# SWM341 register map
File version: 1.0
SWM341 Microcontroller registers
CPU: CM0 r1p0, little endian, MPU, FPU, 2 interrupt priority bits
Registers are 32-bit, read-write, no defined reset value unless marked. A register's access mark holds for its fields unless they carry their own. Offsets are from the block's base; lines under a group give offsets from that group; [hi:lo] are bit positions; {n}, {i} and the like mark numbered series; 'fields as' and 'values as' point back to an identical list; <NAME> marks a mode.

## Memory map
0x40000000 SYS size 0xAA09C — Registers group
0x40000800 DMA size 0x140 — Registers group
0x40001800 SDIO size 0x40 — Registers group
0x40002000 LCD size 0x114 — Registers group
0x40002800 CRC size 0x10 — Registers group
0x40003000 CORDIC size 0x20 — Registers group
0x40003800 DIV size 0x28 — Registers group
0x40004000 GPIOM size 0x80
0x40004800 GPION size 0x80
0x40005000 USBD size 0x4844 — Registers group
0x40005000 USBH size 0x5098 — Registers group
0x4000B000 JPEG size 0x400 — Registers group
0x4000C000 DMA2D size 0x44 — Registers group
0x40040000 GPIOA size 0x80 — Registers group
0x40040800 GPIOB size 0x80
0x40041000 GPIOC size 0x80
0x40041800 GPIOD size 0x80
0x40042000 UART0 size 0x20 — Registers group
0x40042800 UART1 size 0x20
0x40043000 UART2 size 0x20
0x40043800 UART3 size 0x20
0x40044000 SPI0 size 0x1C — Registers group
0x40044800 SPI1 size 0x1C
0x40046000 PWM0 size 0x80 — Registers group
0x40046080 PWM1 size 0x80
0x40046100 PWM2 size 0x80
0x40046180 PWM3 size 0x80
0x40046200 PWM4 size 0x80
0x40046400 PWMG size 0x28 — Registers group
0x40046800 TIMR0 size 0x34 — Registers group
0x40046840 TIMR1 size 0x34
0x40046880 TIMR2 size 0x34
0x400468C0 TIMR3 size 0x34
0x40046900 TIMR4 size 0x34
0x40046C00 TIMRG size 0x44 — Registers group
{0x40048800+0x40*n} BTIMR{n} size 0x34 (n=0..11)
0x40048C00 BTIMRG size 0x44
0x40049000 ADC0 size 0xF4 — Registers group
0x40049800 ADC1 size 0xF4
0x4004A000 FMC size 0x28 — Registers group
0x4004A800 SFC size 0x28 — Registers group
0x4004B800 RTC size 0x34 — Registers group
0x4004C000 DAC size 0x10 — Registers group
0x4004C800 QEI size 0x34 — Registers group
0x400A0000 PORTA size 0x504 — Registers group
0x400A0010 PORTB size 0x504
0x400A0020 PORTC size 0x504
0x400A0030 PORTD size 0x504
0x400A0040 PORTE size 0x504
0x400A0080 PORTM size 0x504
0x400A0090 PORTN size 0x504
0x400A0800 WDT size 0x14 — Registers group
0x400A1000 GPIOE size 0x80
0x400A6000 I2C0 size 0x38 — Registers group
0x400A6800 I2C1 size 0x38
0x400A8000 CAN0 size 0x3C0 — Registers group
0x400A8800 CAN1 size 0x3C0
0x88000000 SDRAMC size 0x14 — Registers group

## Interrupts
0 UART0 — UART0 global interrupt
1 UART1 — UART1 global interrupt
2 TIMR0 — TIMR0 global interrupt
3 TIMR1 — TIMR1 global interrupt
4 DMA — DMA global interrupt
5 SPI0 — SPI0 global interrupt
6 PWM_CH0 (PWM0) — PWM_CH0 global interrupt
7 WDT — WDT global interrupt
8 UART2 — UART2 global interrupt
9 PWM_CH1 (PWM1) — PWM_CH1 global interrupt
10 SARADC0 (ADC0) — SARADC0 global interrupt
11 BTIMER0 (BTIMR0) — BTIMER0 global interrupt
12 HALL0 (TIMRG) — HALL0 global interrupt
13 PWM_CH2 (PWM2) — PWM_CH2 global interrupt
14 PWM_HALT (PWMG) — PWM_HALT global interrupt
15 I2C0 — I2C0 global interrupt
16 CAN0 — CAN0 global interrupt
17 SPI1 — SPI1 global interrupt
18 RTC_BASE (RTC) — RTC_BASE global interrupt
19 PWM_CH3 (PWM3) — PWM_CH3 global interrupt
20 TIMER2 (TIMR2) — TIMER2 global interrupt
21 UART3 — UART3 global interrupt
22 TIMER3 (TIMR3) — TIMER3 global interrupt
23 SARADC1 (ADC1) — SARADC1 global interrupt
24 BOD (SYS) — BOD global interrupt
25 CORDIC — CORDIC global interrupt
26 BTIMER1 (BTIMR1) — BTIMER1 global interrupt
27 PWM_CH4 (PWM4) — PWM_CH4 global interrupt
28 HALL1 (TIMRG) — HALL1 global interrupt

## SYS — Registers group
Base 0x40000000
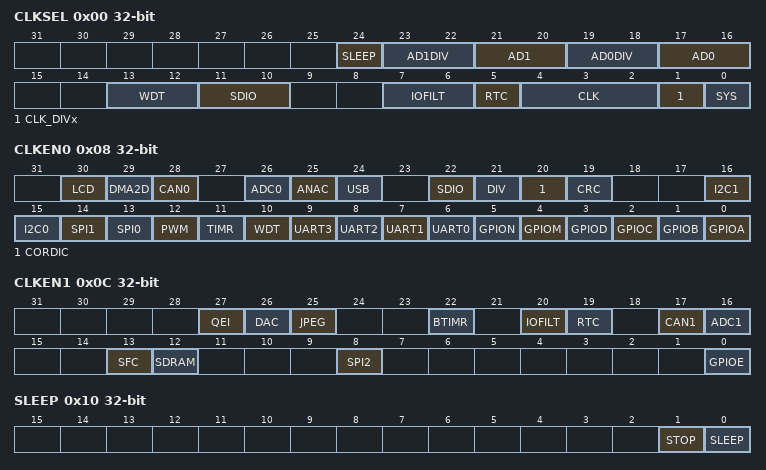
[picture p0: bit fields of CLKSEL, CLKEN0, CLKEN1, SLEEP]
0x00 CLKSEL
  [24] SLEEP, [23:22] AD1DIV, [21:20] AD1, [19:18] AD0DIV, [17:16] AD0, [13:12] WDT, [11:10] SDIO, [7:6] IOFILT, [5] RTC, [4:2] CLK, [1] CLK_DIVx, [0] SYS
0x04 CLKDIVx_ON
0x08 CLKEN0
  [30] LCD, [29] DMA2D, [28] CAN0, [26] ADC0, [25] ANAC, [24] USB, [22] SDIO, [21] DIV, [20] CORDIC, [19] CRC, [16] I2C1, [15] I2C0, [14] SPI1, [13] SPI0, [12] PWM, [11] TIMR, [10] WDT, [n+6] UART{n} (n=0..3), [5] GPION, [4] GPIOM, [3] GPIOD, [2] GPIOC, [1] GPIOB, [0] GPIOA
0x0C CLKEN1
  [27] QEI, [26] DAC, [25] JPEG, [22] BTIMR, [20] IOFILT, [19] RTC, [17] CAN1, [16] ADC1, [13] SFC, [12] SDRAM, [8] SPI2, [0] GPIOE
0x10 SLEEP
  [1] STOP, [0] SLEEP
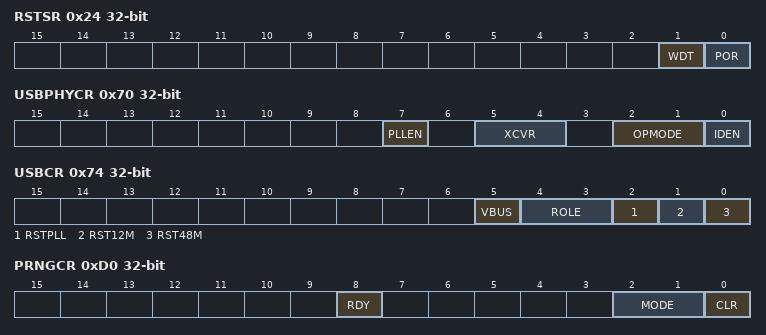
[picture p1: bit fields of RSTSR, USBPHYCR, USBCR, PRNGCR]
0x24 RSTSR
  [1] WDT, [0] POR
0x30 RTCWKCR
  [0] EN
0x34 RTCWKSR
  [0] FLAG
0x70 USBPHYCR
  [7] PLLEN, [5:4] XCVR, [2:1] OPMODE, [0] IDEN
0x74 USBCR
  [5] VBUS, [4:3] ROLE, [2] RSTPLL, [1] RST12M, [0] RST48M
{0x80+4i} CHIPID[{i}] (i=0..3) ro
{0x90+4i} BACKUP[{i}] (i=0..3)
0xD0 PRNGCR
  [8] RDY, [2:1] MODE, [0] CLR
0xD4 PRNGDL
0xD8 PRNGDH
0x100 PAWKEN
0x104 PBWKEN
0x108 PCWKEN
0x10C PDWKEN
0x110 PEWKEN
0x120 PMWKEN
0x124 PNWKEN
0x130 PAWKSR
0x134 PBWKSR
0x138 PCWKSR
0x13C PDWKSR
0x140 PEWKSR
0x150 PMWKSR
0x154 PNWKSR
0x400 IOFILT0
0x404 IOFILT1
0x720 PRSTEN
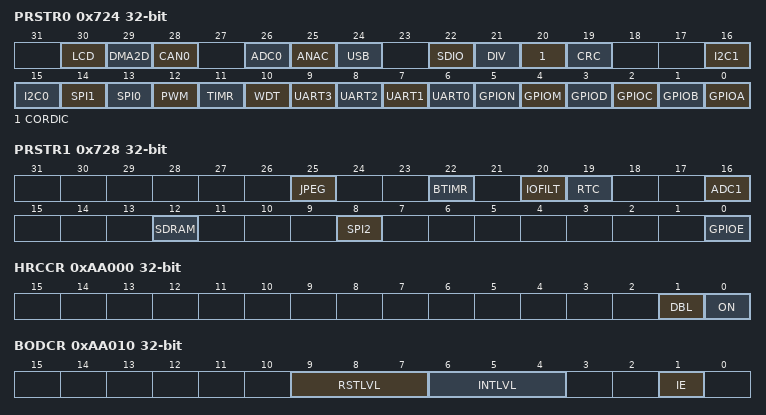
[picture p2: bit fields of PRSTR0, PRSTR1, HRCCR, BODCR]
0x724 PRSTR0
  fields as CLKEN0
0x728 PRSTR1
  [25] JPEG, [22] BTIMR, [20] IOFILT, [19] RTC, [16] ADC1, [12] SDRAM, [8] SPI2, [0] GPIOE
0xAA000 HRCCR
  [1] DBL, [0] ON
0xAA010 BODCR
  [9:7] RSTLVL, [6:4] INTLVL, [1] IE
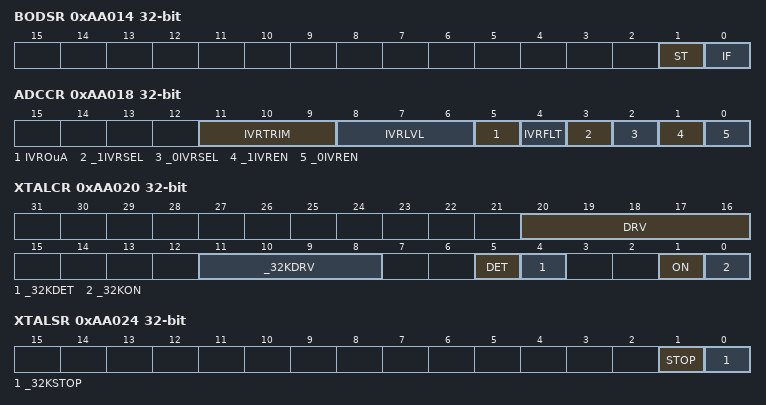
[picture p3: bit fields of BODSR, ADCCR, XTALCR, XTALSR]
0xAA014 BODSR
  [1] ST, [0] IF
0xAA018 ADCCR
  [11:9] IVRTRIM, [8:6] IVRLVL, [5] IVROuA, [4] IVRFLT, [3] _1IVRSEL, [2] _0IVRSEL, [1] _1IVREN, [0] _0IVREN
0xAA020 XTALCR
  [20:16] DRV, [11:8] _32KDRV, [5] DET, [4] _32KDET, [1] ON, [0] _32KON
0xAA024 XTALSR
  [1] STOP, [0] _32KSTOP
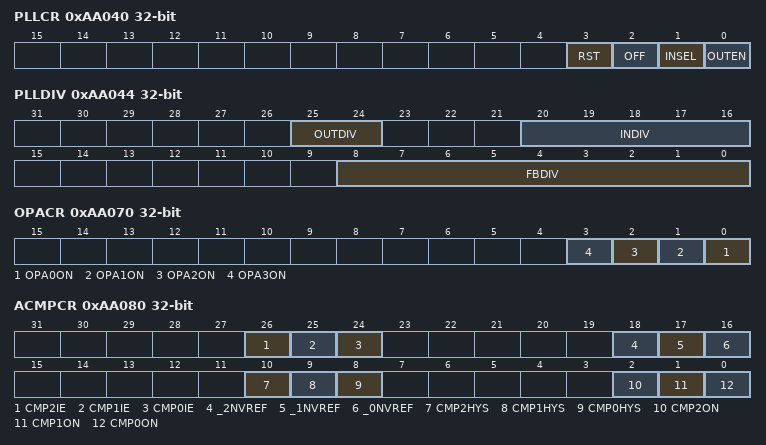
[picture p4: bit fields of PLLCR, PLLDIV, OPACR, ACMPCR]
0xAA040 PLLCR
  [3] RST, [2] OFF, [1] INSEL, [0] OUTEN
0xAA044 PLLDIV
  [25:24] OUTDIV, [20:16] INDIV, [8:0] FBDIV
0xAA04C PLLLOCK
0xAA050 LRCCR
  [0] ON
0xAA070 OPACR
  [n] OPA{n}ON (n=0..3)
0xAA080 ACMPCR
  [26] CMP2IE, [25] CMP1IE, [24] CMP0IE, [18] _2NVREF, [17] _1NVREF, [16] _0NVREF, [10] CMP2HYS, [9] CMP1HYS, [8] CMP0HYS, [2] CMP2ON, [1] CMP1ON, [0] CMP0ON
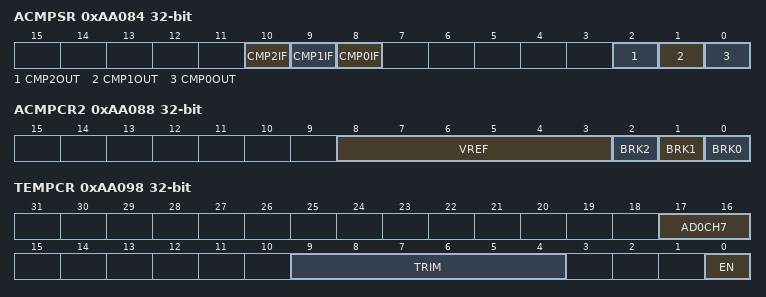
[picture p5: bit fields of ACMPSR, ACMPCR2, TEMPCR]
0xAA084 ACMPSR
  [10] CMP2IF, [9] CMP1IF, [8] CMP0IF, [2] CMP2OUT, [1] CMP1OUT, [0] CMP0OUT
0xAA088 ACMPCR2
  [8:3] VREF, [2] BRK2, [1] BRK1, [0] BRK0
0xAA090 DACCR
  [4:0] VRADJ
0xAA098 TEMPCR
  [17:16] AD0CH7, [9:4] TRIM, [0] EN
